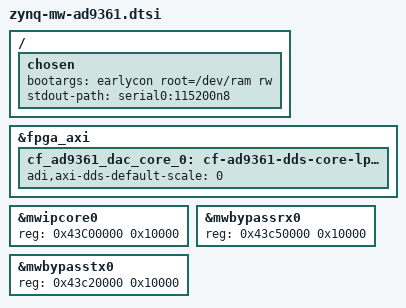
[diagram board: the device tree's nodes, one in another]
/* Setup the default boot args for ramdisk and earlycon */
/ {
	chosen {
		/delete-property/ linux,stdout-path;
		bootargs = "earlycon root=/dev/ram rw";		
		stdout-path = "serial0:115200n8";
	};
};

&fpga_axi {
	/delete-node/ mwipcore@43c00000;
    cf_ad9361_dac_core_0: cf-ad9361-dds-core-lpc@79024000 {
        /* Mute DDS by default */
        adi,axi-dds-default-scale = <0>;
    };
};

#include "zynq-mw-axilite-common.dtsi"
#include "mw-aximm-common.dtsi"
#include "zynq-mw-cma.dtsi"
#include "zynq-mw-ad9361-bypass-user-logic.dtsi"

&mwipcore0 {
	reg = <0x43C00000 0x10000>;
};

&mwbypassrx0 { 
	reg = <0x43c50000 0x10000>;
};
&mwbypasstx0 { 
	reg = <0x43c20000 0x10000>;
};
